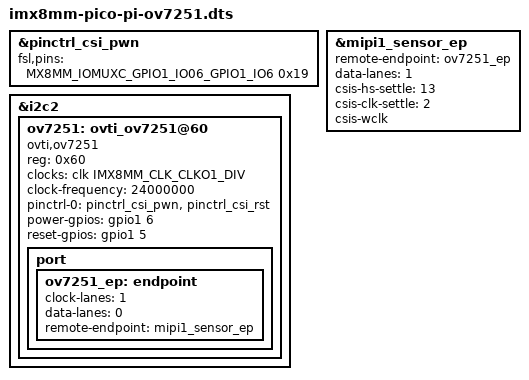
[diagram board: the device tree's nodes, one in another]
/*
 * Copyright 2019 TechNexion Ltd.
 * Copyright 2018 NXP
 *
 * Author: Leo Wang <leo.wang@technexion.com>
 *
 * This program is free software; you can redistribute it and/or
 * modify it under the terms of the GNU General Public License
 * as published by the Free Software Foundation; either version 2
 * of the License, or (at your option) any later version.
 *
 * This program is distributed in the hope that it will be useful,
 * but WITHOUT ANY WARRANTY; without even the implied warranty of
 * MERCHANTABILITY or FITNESS FOR A PARTICULAR PURPOSE.  See the
 * GNU General Public License for more details.
 */

#include "imx8mm-pico-pi.dts"

&pinctrl_csi_pwn {
	fsl,pins = <
		MX8MM_IOMUXC_GPIO1_IO06_GPIO1_IO6	0x19
	>;
};

&i2c2 {
	ov7251: ovti_ov7251@60 {
		compatible = "ovti,ov7251";
		reg = <0x60>;

		clocks = <&clk IMX8MM_CLK_CLKO1_DIV>;
		clock-names = "xclk";
		clock-frequency = <24000000>;

		pinctrl-names = "default";
		pinctrl-0 = <&pinctrl_csi_pwn>, <&pinctrl_csi_rst>;

		power-gpios = <&gpio1 6 GPIO_ACTIVE_HIGH>;
		reset-gpios = <&gpio1 5 GPIO_ACTIVE_HIGH>;
		status = "okay";

		port {
			ov7251_ep: endpoint {
				clock-lanes = <1>;
				data-lanes = <0>;
				remote-endpoint = <&mipi1_sensor_ep>;
			};
		};
	};
};

&mipi1_sensor_ep {
	remote-endpoint = <&ov7251_ep>;
	data-lanes = <1>;
	csis-hs-settle = <13>;
	csis-clk-settle = <2>;
	csis-wclk;
};
